# STM32WL5X_CM0P register map
File version: 2.1
CPU: CM0 r0p1, little endian, MPU, no FPU, 4 interrupt priority bits
Registers are 32-bit, read-write, reset 0x0 unless marked. A register's access mark holds for its fields unless they carry their own. Offsets are from the block's base; [hi:lo] are bit positions; {n}, {i} and the like mark numbered series; 'fields as' and 'values as' point back to an identical list.

## TAMP — Tamper and backup registers
Base 0x4000B000
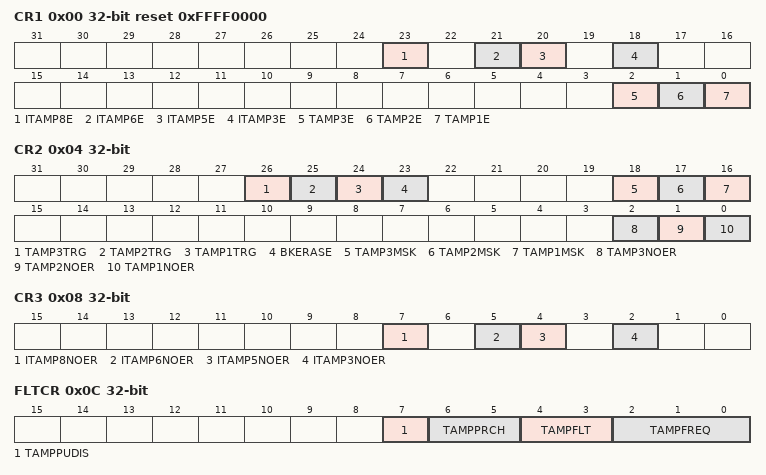
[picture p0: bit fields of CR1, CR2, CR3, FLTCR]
0x00 CR1 reset 0xFFFF0000 — control register 1
  [23] ITAMP8E
    0=Disabled (Internal tamper x disabled); 1=Enabled (Internal tamper x enabled)
  [21] ITAMP6E
    values as ITAMP8E
  [20] ITAMP5E
    values as ITAMP8E
  [18] ITAMP3E
    values as ITAMP8E
  [2] TAMP3E — TAMP2E
    0=Disabled (Tamper detection on TAMP_INx is disabled); 1=Enabled (Tamper detection on TAMP_IN3 is enabled)
  [1] TAMP2E
    values as TAMP3E
  [0] TAMP1E
    values as TAMP3E
0x04 CR2 — control register 2
  [26] TAMP3TRG
    0=FilteredLowOrUnfilteredHigh (If TAMPFLT != 00 Tamper x input staying low triggers a tamper detection event. If TAMPFLT = 00 Tamper x input rising edge and high level triggers a tamper detection event); 1=FilteredHighOrUnfilteredLow (If TAMPFLT != 00 Tamper x input staying high triggers a tamper detection event. If TAMPFLT = 00 Tamper x input falling edge and low level triggers a tamper detection event)
  [25] TAMP2TRG
    values as TAMP3TRG
  [24] TAMP1TRG
    values as TAMP3TRG
  [23] BKERASE — Backup registerserase
    on write: 1=Reset backup registers
  [18] TAMP3MSK
    0=ResetBySoftware (Tamper x event generates a trigger event and TAMPxF must be cleared by software to allow next tamper event detection); 1=ResetByHardware (Tamper x event generates a trigger event. TAMPxF is masked and internally cleared by hardware. The backup registers are not erased. The tamper x interrupt must not be enabled when TAMP3MSK is set)
  [17] TAMP2MSK
    values as TAMP3MSK
  [16] TAMP1MSK
    values as TAMP3MSK
  [2] TAMP3NOER
    0=Erase (Tamper x event erases the backup registers); 1=NotErase (Tamper x event does not erase the backup registers)
  [1] TAMP2NOER
    values as TAMP3NOER
  [0] TAMP1NOER
    values as TAMP3NOER
0x08 CR3 — TAMP control register 3
  [all] fields
    0=Erase (Internal tamper x event erases the backup registers); 1=NotErase (Internal tamper x event does not erase the backup registers)
  [7] ITAMP8NOER
  [5] ITAMP6NOER
  [4] ITAMP5NOER
  [2] ITAMP3NOER
0x0C FLTCR — TAMP filter control register
  [7] TAMPPUDIS
    0=Enabled (Precharge TAMP_INx pins before sampling (enable internal pull-up)); 1=Disabled (Disable precharge of TAMP_INx pins)
  [6:5] TAMPPRCH
    0=Cycles1 (1 RTCCLK cycle); 1=Cycles2 (2 RTCCLK cycles); 2=Cycles4 (4 RTCCLK cycles); 3=Cycles8 (8 RTCCLK cycles)
  [4:3] TAMPFLT
    0=NoFilter (Tamper event is activated on edge of TAMP_INx input transitions to the active level (no internal pull-up on TAMP_INx input)"); 1=Filter2 (Tamper event is activated after 2 consecutive samples at the active level"); 2=Filter4 (Tamper event is activated after 4 consecutive samples at the active level"); 3=Filter8 (Tamper event is activated after 8 consecutive samples at the active level")
  [2:0] TAMPFREQ
    0=Hz_1 (RTCCLK / 32768 (1 Hz when RTCCLK = 32768 Hz)); 1=Hz_2 (RTCCLK / 16384 (2 Hz when RTCCLK = 32768 Hz)); 2=Hz_4 (RTCCLK / 8192 (4 Hz when RTCCLK = 32768 Hz)); 3=Hz_8 (RTCCLK / 4096 (8 Hz when RTCCLK = 32768 Hz)); 4=Hz_16 (RTCCLK / 2048 (16 Hz when RTCCLK = 32768 Hz)); 5=Hz_32 (RTCCLK / 1024 (32 Hz when RTCCLK = 32768 Hz)); 6=Hz_64 (RTCCLK / 512 (64 Hz when RTCCLK = 32768 Hz)); 7=Hz_128 (RTCCLK / 256 (128 Hz when RTCCLK = 32768 Hz))
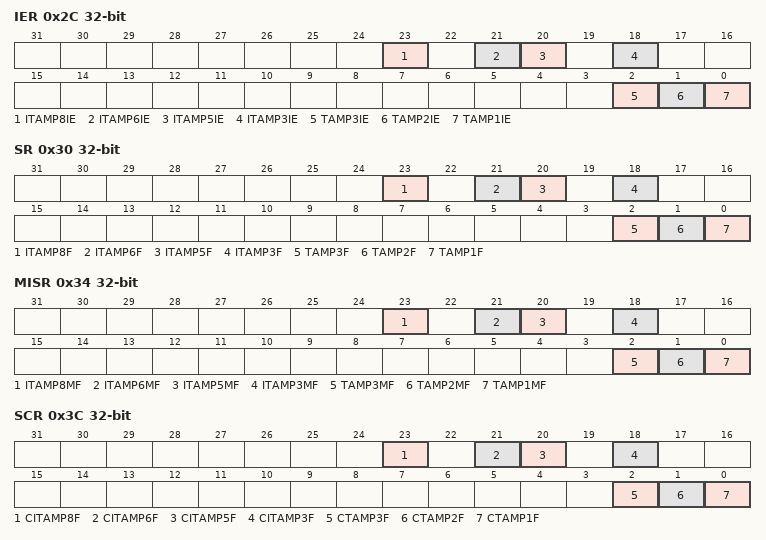
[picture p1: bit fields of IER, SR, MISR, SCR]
0x2C IER — TAMP interrupt enable register
  [23] ITAMP8IE
    0=Disabled (Internal tamper x interrupt disabled); 1=Enabled (Internal tamper x interrupt enabled)
  [21] ITAMP6IE
    values as ITAMP8IE
  [20] ITAMP5IE
    values as ITAMP8IE
  [18] ITAMP3IE
    values as ITAMP8IE
  [2] TAMP3IE
    0=Disabled (Tamper x interrupt disabled); 1=Enabled (Tampoer x interrupt enabled)
  [1] TAMP2IE
    values as TAMP3IE
  [0] TAMP1IE
    values as TAMP3IE
0x30 SR ro — TAMP status register
  [23] ITAMP8F
    0=Idle (No tamper detected); 1=Tamper (Internal tamper detected)
  [21] ITAMP6F
    values as ITAMP8F
  [20] ITAMP5F
    values as ITAMP8F
  [18] ITAMP3F
    values as ITAMP8F
  [2] TAMP3F
    0=Idle (No tamper detected); 1=Tamper detected
  [1] TAMP2F
    0=Idle (No tamper detected); 1=Tamper detected
  [0] TAMP1F
    0=Idle (No tamper detected); 1=Tamper detected
0x34 MISR ro — TAMP masked interrupt status register
  [23] ITAMP8MF
    0=Idle (No tamper detected - Masked); 1=Tamper (Internal tamper detected - Masked)
  [21] ITAMP6MF
    values as ITAMP8MF
  [20] ITAMP5MF
    values as ITAMP8MF
  [18] ITAMP3MF
    values as ITAMP8MF
  [2] TAMP3MF
    0=Idle (No tamper detected - Masked); 1=Tamper detected - Masked
  [1] TAMP2MF
    values as TAMP3MF
  [0] TAMP1MF
    values as TAMP3MF
0x3C SCR wo — TAMP status clear register
  [all] fields
    1=Clear tamper flag
  [23] CITAMP8F
  [21] CITAMP6F
  [20] CITAMP5F
  [18] CITAMP3F
  [2] CTAMP3F
  [1] CTAMP2F
  [0] CTAMP1F
0x40 COUNTR ro — monotonic counter register
  [31:0] COUNT
{0x100+4i} BKP{i}R (i=0..19) — TAMP backup register
  [31:0] BKP
